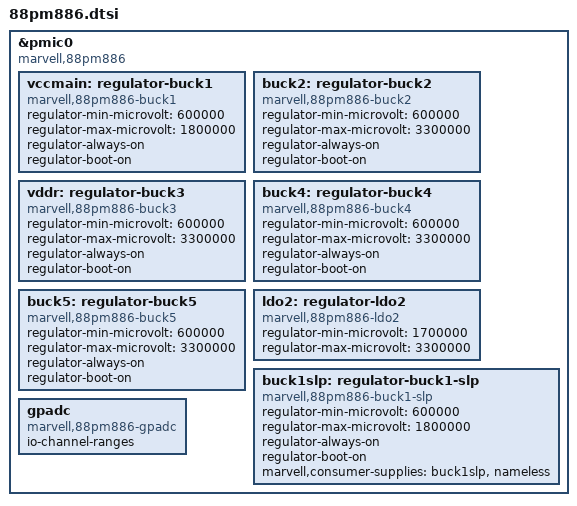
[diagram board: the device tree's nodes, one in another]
/*
 * Copyright (C) 2014 Marvell
 * Yi Zhang <yizhang@marvell.com>
 */

/*
 * Integrated Power Management Chip
 * header file for Marvell PMIC: 88pm886
 */

&pmic0 {
	compatible = "marvell,88pm886";
	/* ---buck--- */
	vccmain: regulator-buck1 {
		compatible = "marvell,88pm886-buck1";
		regulator-min-microvolt = <600000>;
		regulator-max-microvolt = <1800000>;
		regulator-always-on;
		regulator-boot-on;
	};
	buck2: regulator-buck2 {
		compatible = "marvell,88pm886-buck2";
		regulator-min-microvolt = <600000>;
		regulator-max-microvolt = <3300000>;
		regulator-always-on;
		regulator-boot-on;
	};
	vddr: regulator-buck3 {
		compatible = "marvell,88pm886-buck3";
		regulator-min-microvolt = <600000>;
		regulator-max-microvolt = <3300000>;
		regulator-always-on;
		regulator-boot-on;
	};
	buck4: regulator-buck4 {
		compatible = "marvell,88pm886-buck4";
		regulator-min-microvolt = <600000>;
		regulator-max-microvolt = <3300000>;
		regulator-always-on;
		regulator-boot-on;
	};
	buck5: regulator-buck5 {
		compatible = "marvell,88pm886-buck5";
		regulator-min-microvolt = <600000>;
		regulator-max-microvolt = <3300000>;
		regulator-always-on;
		regulator-boot-on;
	};

	/* ---ldo--- */
	ldo2: regulator-ldo2 {
		compatible = "marvell,88pm886-ldo2";
		regulator-min-microvolt = <1700000>;
		regulator-max-microvolt = <3300000>;
	};

	/* virtual regulator */
	buck1slp: regulator-buck1-slp {
		compatible = "marvell,88pm886-buck1-slp";
		regulator-min-microvolt = <600000>;
		regulator-max-microvolt = <1800000>;
		regulator-always-on;
		regulator-boot-on;
		marvell,consumer-supplies = "buck1slp", "nameless";
	};

	gpadc: gpadc{
	        compatible = "marvell,88pm886-gpadc";
		#io-channel-cells = <1>;
		io-channel-ranges;
	};
};
